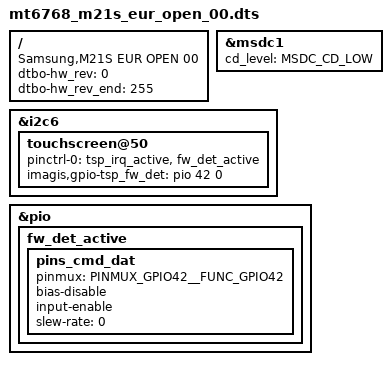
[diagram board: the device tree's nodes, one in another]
/* Generated by MediaTek
 * If these files should be chaned, then please make a sync with MTK
*/

/dts-v1/;
/plugin/;

#include "../mediatek/k68v1_64_titan.dts"
#include "mt6768-m21s_common.dtsi"
#include "cust_m21s_eur_open-gpio00.dtsi"
#include "mt6768_m21s_camera_00.dtsi"
#include "mt6768_m21s_nfc_00.dtsi"
#include "mt6768_m21s_mst_00.dtsi"
#include "mt6768_m21s_sensorhub_00.dtsi"
#include "battery-data-m21s-eur-open-common.dtsi"
#include "mt6768_m21s_sensor_grip_00.dtsi"
#include "mt6768_m21s_fingerprint-sensor_00.dtsi"
#include "s2mu106_motor.dtsi"
#include "mt6768_m21s_input_common.dtsi"
#include "mt6768_m21s_pm_common.dtsi"
#include "mt6768_m21s_audio_common.dtsi"

/* Add Samsung configuration over here */
/ {
	compatible = "Samsung,M21S EUR OPEN 00", "Mediatek,MT6768";
	dtbo-hw_rev = <0>;
	dtbo-hw_rev_end = <255>;
};

&msdc1 {
	cd_level = /bits/ 8 <MSDC_CD_LOW>;
};

&i2c6 {
	touchscreen@50 {
		pinctrl-0 = <&tsp_irq_active &fw_det_active>;
		imagis,gpio-tsp_fw_det = <&pio 42 0>;
	};
};

&pio {
	fw_det_active: fw_det_active {
		pins_cmd_dat {
			pinmux = <PINMUX_GPIO42__FUNC_GPIO42>;
			bias-disable;
			input-enable;
			slew-rate = <0>;
		};
	};
};

/*End of this file, DO NOT ADD ANYTHING HERE*/
